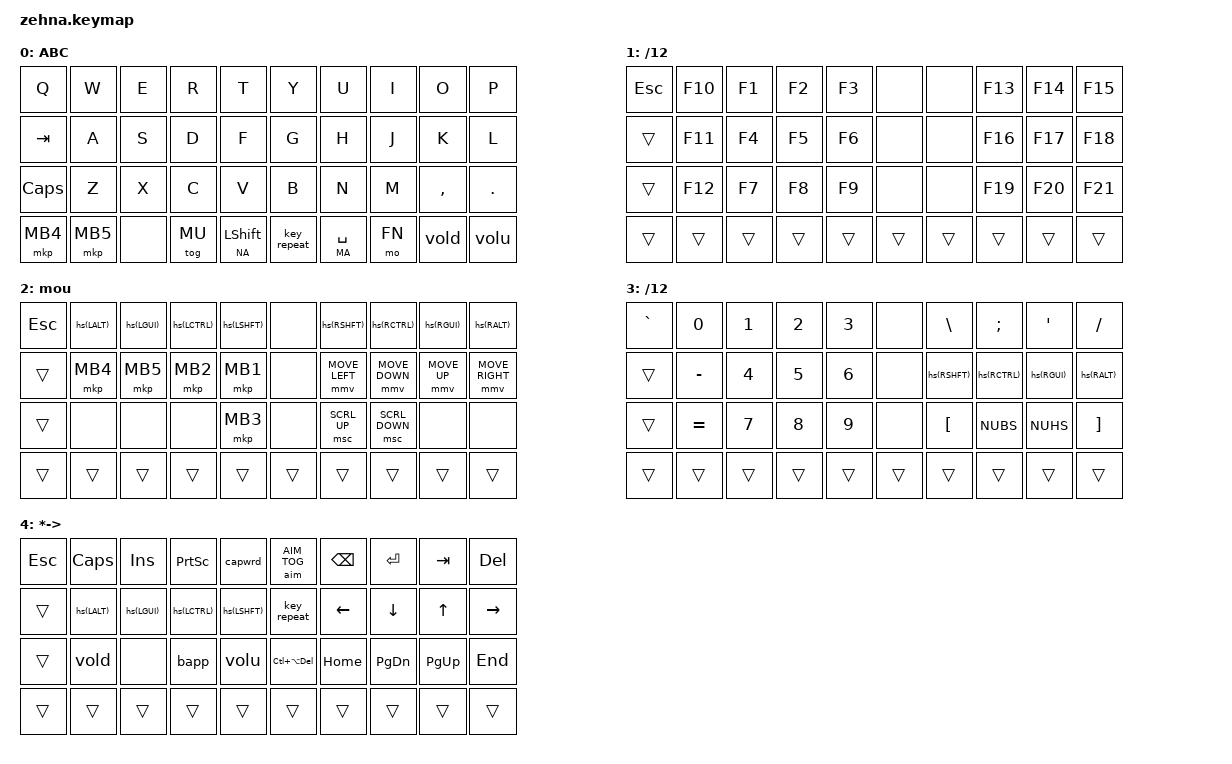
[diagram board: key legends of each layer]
#include <behaviors.dtsi>
#include <dt-bindings/zmk/keys.h>
// #include <dt-bindings/zmk/bt.h>
#include <behaviors/anti_idle_mode.dtsi>
#include <behaviors/battery_percentage_printer.dtsi>
#include <dt-bindings/anti_idle_mode.h>

&caps_word { continue-list = <MINUS UNDERSCORE BSPC DEL LEFT RIGHT DOT COMMA SEMI SLASH>; };
&sl { release-after-ms = <800>;  /delete-property/ quick-release; };

#define xxxx &none
#define ____ &trans

#define hs(l) &hsk l l 

#define FN 1
#define MU 2
#define MA 3
#define NA 4
#define RST &to 0
#define LCKS &kp LC(LA(DEL))

#define ZMK_MOUSE_DEFAULT_MOVE_VAL 50000  // 600
#define ZMK_MOUSE_DEFAULT_SCRL_VAL 50000  // 10
#include <dt-bindings/zmk/pointing.h>
&mmv {
  acceleration-exponent = <1>;      // 1
  time-to-max-speed-ms = <400>;    // 40
};
&msc {
  acceleration-exponent = <1>;      // 0
  time-to-max-speed-ms = <400>;   // 500
};

/ { 
    macros {
//        layshf: lay_shift { compatible = "zmk,behavior-macro-one-param"; wait-ms = <0>; tap-ms = <0>; #binding-cells = <1>;
//                            bindings = <&macro_param_1to1>, <&macro_tap &to MACRO_PLACEHOLDER>,  <&macro_press &kp LSHFT>, <&macro_pause_for_release>, <&macro_release &kp LSHFT>, <&macro_tap &to 0>; };
        ltg: layer_tog    { compatible = "zmk,behavior-macro-one-param"; wait-ms = <0>; tap-ms = <1>; #binding-cells = <1>;
                            bindings = <&macro_tap &kp K_CANCEL>, <&macro_param_1to1>, <&macro_tap &tog MACRO_PLACEHOLDER>; };
        capwrd: capsword  { compatible = "zmk,behavior-macro"; wait-ms = <0>; tap-ms = <1>; #binding-cells = <0>;
                            bindings = <&macro_tap &kp K_CANCEL &caps_word>; };
        parens: parens    { compatible = "zmk,behavior-macro"; wait-ms = <0>; tap-ms = <1>; #binding-cells = <0>;
                            bindings = <&macro_tap &kp LPAR &kp RPAR &kp LEFT>; };
        rp: reset_kp      { compatible = "zmk,behavior-macro-one-param"; wait-ms = <0>; tap-ms = <0>; #binding-cells = <1>;
                            bindings = <&macro_tap &kp K_CANCEL>, <&macro_param_1to1>, <&macro_tap &kp MACRO_PLACEHOLDER>; };
    };

    behaviors {
        sm: stick_mod       { compatible = "zmk,behavior-sticky-key"; #binding-cells = <1>; bindings = <&kp>; release-after-ms = <2000>; quick-release; ignore-modifiers; };
        hsk: holdstickymod  { compatible = "zmk,behavior-hold-tap";   #binding-cells = <2>; flavor = "balanced";        tapping-term-ms = <250>; bindings = <&kp>, <&sm>; }; 
        lkp: molayer_kp     { compatible = "zmk,behavior-hold-tap";   #binding-cells = <2>; flavor = "balanced";        tapping-term-ms = <250>; bindings = <&mo>, <&kp>; }; 
        lsm: molayer_sm     { compatible = "zmk,behavior-hold-tap";   #binding-cells = <2>; flavor = "balanced";        tapping-term-ms = <250>; bindings = <&mo>, <&sm>; }; 
        slm: sl_mo          { compatible = "zmk,behavior-hold-tap";   #binding-cells = <2>; flavor = "balanced";        tapping-term-ms = <300>; bindings = <&mo>, <&sl>; }; 
        mtg: mo_tog         { compatible = "zmk,behavior-hold-tap";   #binding-cells = <2>; flavor = "hold-preferred";  tapping-term-ms = <300>; bindings = <&mo>, <&tog>; }; 
//        kkp: holdkp_kp      { compatible = "zmk,behavior-hold-tap";   #binding-cells = <2>; flavor = "balanced";        tapping-term-ms = <400>; bindings = <&kp>, <&kp>; }; 
//        cw: kp_capwrd       { compatible = "zmk,behavior-hold-tap";   #binding-cells = <2>; flavor = "balanced"; tapping-term-ms = <200>; bindings = <&kp>, <&capwrd>; };
//        symi: symtap        { compatible = "zmk,behavior-hold-tap";   #binding-cells = <2>; flavor = "balanced"; tapping-term-ms = <200>; bindings = <&numshf>, <&sl>; }; 
//        blt: bluetoot     { compatible = "zmk,behavior-mod-morph";  #binding-cells = <0>; bindings = <&bt BT_NXT>, <&bt BT_CLR>; mods = <MOD_RALT>; };
//        pars: parentheses   { compatible = "zmk,behavior-mod-morph";  #binding-cells = <0>; bindings = <&kp LPAR>, <&kp RPAR>; mods = <(MOD_LSFT|MOD_RSFT)>; };
        vold: volume_dw_mute { compatible = "zmk,behavior-mod-morph";  #binding-cells = <0>; bindings = <&kp C_VOL_DN>, <&kp C_MUTE>; mods = <(MOD_LGUI|MOD_RGUI)>; };
        volu: volume_up_mute { compatible = "zmk,behavior-mod-morph";  #binding-cells = <0>; bindings = <&kp C_VOL_UP>, <&kp C_MUTE>; mods = <(MOD_LGUI|MOD_RGUI)>; };
//        capw: cw_capsword   { compatible = "zmk,behavior-mod-morph";  #binding-cells = <0>; bindings = <&capwrd>, <&kp CAPS>; mods = <(MOD_LSFT|MOD_RSFT)>; };
    };

    anti_idle {
        compatible = "zmk,anti-idle-generic";
        interval-ms = <60000>; // How often to send actions (ms)
        bindings = <&kp LEFT &kp RIGHT>; // Actions to perform (e.g., mouse move)
        tap_ms = <400>;  // Duration of each action (ms)
        wait_ms = <400>; // Delay between actions (ms)
    };


    keymap {
        compatible = "zmk,keymap";
        abc {
            display-name = "ABC";
            bindings = <
            //  0           1           2           3           4           5           6           7           8           9
                &kp Q       &kp W       &kp E       &kp R       &kp T       &kp Y       &kp U       &kp I       &kp O       &kp P 
                &kp TAB     &kp A       &kp S       &kp D       &kp F       &kp G       &kp H       &kp J       &kp K       &kp L 
                &kp CAPS    &kp Z       &kp X       &kp C       &kp V       &kp B       &kp N       &kp M       &kp COMMA   &kp DOT 
                &mkp MB4    &mkp MB5    xxxx       &tog MU  &lsm NA LSHFT  &key_repeat  &lkp MA SPACE  &mo FN   &vold       &volu 
            >; 
        };

        fun {
            display-name = "/12";
            bindings = < 
            //  1           2           3           4           5           6           7           8           9           10 
                &kp ESC     &kp F10     &kp F1      &kp F2      &kp F3      xxxx        xxxx        &kp F13     &kp F14     &kp F15     
                ____        &kp F11     &kp F4      &kp F5      &kp F6      xxxx        xxxx        &kp F16     &kp F17     &kp F18
                ____        &kp F12     &kp F7      &kp F8      &kp F9      xxxx        xxxx        &kp F19     &kp F20     &kp F21
                ____        ____        ____        ____        ____        ____        ____        ____        ____        ____  
            >; 
        };

        mou {
            display-name = "mou";
            bindings = <
            //  1           2           3           4           5           6           7           8           9           10 
                &kp ESC     hs(LALT)    hs(LGUI)    hs(LCTRL)   hs(LSHFT)   xxxx        hs(RSHFT)   hs(RCTRL)   hs(RGUI)    hs(RALT)  
                ____        &mkp MB4    &mkp MB5    &mkp MB2    &mkp MB1    xxxx        &mmv MOVE_LEFT &mmv MOVE_DOWN &mmv MOVE_UP &mmv MOVE_RIGHT 
                ____        xxxx        xxxx        xxxx        &mkp MB3    xxxx        &msc SCRL_UP &msc SCRL_DOWN  xxxx   xxxx 
                ____        ____        ____        ____        ____        ____        ____        ____        ____        ____  
            >; 
        };  

        mat {
            display-name = "/12";
            bindings = < 
            //  1           2           3           4           5           6           7           8           9           10 
                &kp GRAVE   &kp N0      &kp N1      &kp N2      &kp N3      xxxx        &kp BSLH    &kp SEMI    &kp SQT     &kp SLASH
                ____        &kp MINUS   &kp N4      &kp N5      &kp N6      xxxx        hs(RSHFT)   hs(RCTRL)   hs(RGUI)    hs(RALT)  
                ____        &kp EQUAL   &kp N7      &kp N8      &kp N9      xxxx        &kp LBKT    &kp NUBS    &kp NUHS    &kp RBKT
                ____        ____        ____        ____        ____        ____        ____        ____        ____        ____  
            >; 
        };

        nav {
            display-name = "*->";
            bindings = < 
            //  1           2           3           4           5           6           7           8           9           10 
                &kp ESC     &kp CAPS    &kp INS     &kp PSCRN   &capwrd   &aim AIM_TOG  &kp BSPC    &kp ENTER   &kp TAB     &kp DEL 
                ____        hs(LALT)    hs(LGUI)    hs(LCTRL)   hs(LSHFT)   &key_repeat &kp LEFT    &kp DOWN    &kp UP      &kp RIGHT
                ____        &vold       xxxx        &bapp       &volu       LCKS        &kp HOME    &kp PG_DN   &kp PG_UP   &kp END 
                ____        ____        ____        ____        ____        ____        ____        ____        ____        ____  
            >; 
        };
        
    }; 
};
